# FM33A0XXER register map
File version: 1.0
CPU: SC000, little endian, no MPU, no FPU, 3 interrupt priority bits
Registers are 32-bit, read-write, reset 0x0 unless marked. A register's access mark holds for its fields unless they carry their own. Offsets are from the block's base; [hi:lo] are bit positions.

## UART — UART module information
Base 0x40017C00
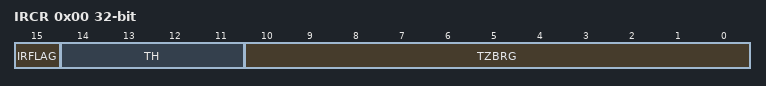
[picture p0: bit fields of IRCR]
0x00 IRCR — Infrared modulation Control Register
  [15] IRFLAG — IRFLAG field description
  [14:11] TH — TH field description
  [10:0] TZBRG — TZBRG field description

## UART0 — UART0 module information
Base 0x40012000
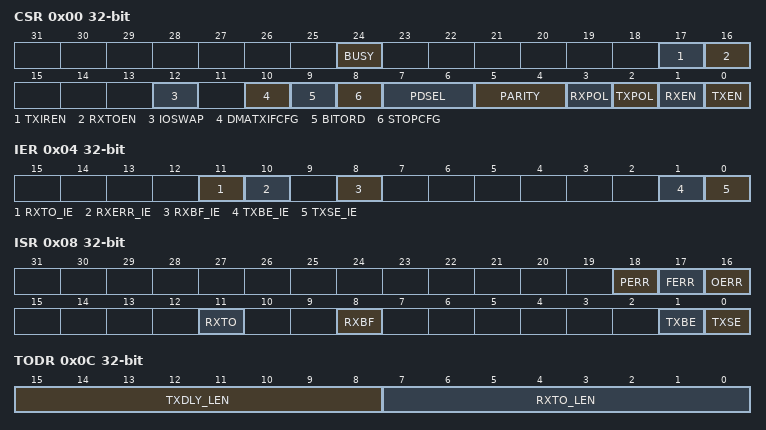
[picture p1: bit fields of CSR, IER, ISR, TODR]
0x00 CSR — UART0 Control Status Register
  [24] BUSY ro — BUSY field description
  [17] TXIREN — TXIREN field description
  [16] RXTOEN — RXTOEN field description
  [12] IOSWAP — IOSWAP field description
  [10] DMATXIFCFG — DMATXIFCFG field description
  [9] BITORD — BITORD field description
  [8] STOPCFG — STOPCFG field description
  [7:6] PDSEL — PDSEL field description
  [5:4] PARITY — PARITY field description
  [3] RXPOL — RXPOL field description
  [2] TXPOL — TXPOL field description
  [1] RXEN — RXEN field description
  [0] TXEN — TXEN field description
0x04 IER — UART0 Interrupt Enable Register
  [11] RXTO_IE — RXTO_IE field description
  [10] RXERR_IE — RXERR_IE field description
  [8] RXBF_IE — RXBF_IE field description
  [1] TXBE_IE — TXBE_IE field description
  [0] TXSE_IE — TXSE_IE field description
0x08 ISR — UART0 Interrupt Status Register
  [18] PERR — PERR field description
  [17] FERR — FERR field description
  [16] OERR — OERR field description
  [11] RXTO — RXTO field description
  [8] RXBF — RXBF field description
  [1] TXBE — TXBE field description
  [0] TXSE — TXSE field description
0x0C TODR — UART0 Time-Out and Delay Register
  [15:8] TXDLY_LEN — TXDLY_LEN field description
  [7:0] RXTO_LEN — RXTO_LEN field description
0x10 RXBUF — UART0 Receive Buffer
  [8:0] RXBUF ro — RXBUF field description
0x14 TXBUF — UART0 Transmit Buffer
  [8:0] TXBUF — TXBUF field description
0x18 BGR reset 0x341 — UART0 Baud rate Generator Register
  [15:0] SPBRG — SPBRG field description

## UART1 — UART1 module information
Base 0x40016800
Registers as UART0 (with UART0 read as UART1).

## UART2 — UART2 module information
Base 0x40016C00
Registers as UART0 (with UART0 read as UART2), without TODR.

## UART3 — UART3 module information
Base 0x40017000
Registers as UART0 (with UART0 read as UART3), without TODR; these are added or differ:
0x14 TXBUF — UART3Transmit Buffer
  [8:0] TXBUF — TXBUF field description

## UART4 — UART4 module information
Base 0x40017400
Registers as UART0 (with UART0 read as UART4), without TODR.

## UART5 — UART5 module information
Base 0x40017800
Registers as UART0 (with UART0 read as UART5), without TODR.

## LPUART0 — LPUART0 module information
Base 0x40014000
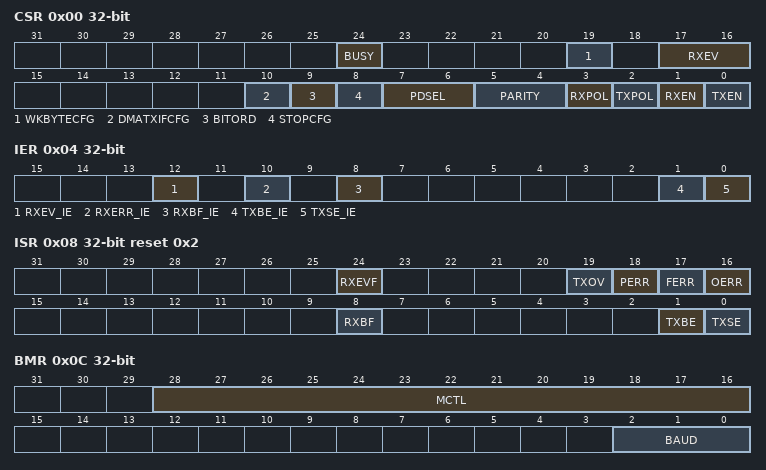
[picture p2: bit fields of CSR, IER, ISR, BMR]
0x00 CSR — LPUART0 Control Status Register
  [24] BUSY ro — BUSY field description
  [19] WKBYTECFG — WKBYTECFG field description
  [17:16] RXEV — RXEV field description
  [10] DMATXIFCFG — DMATXIFCFG field description
  [9] BITORD — BITORD field description
  [8] STOPCFG — STOPCFG field description
  [7:6] PDSEL — PDSEL field description
  [5:4] PARITY — PARITY field description
  [3] RXPOL — RXPOL field description
  [2] TXPOL — TXPOL field description
  [1] RXEN — RXEN field description
  [0] TXEN — TXEN field description
0x04 IER — LPUART0 Interrupt Enable Register
  [12] RXEV_IE — RXEV_IE field description
  [10] RXERR_IE — RXERR_IE field description
  [8] RXBF_IE — RXBF_IE field description
  [1] TXBE_IE — TXBE_IE field description
  [0] TXSE_IE — TXSE_IE field description
0x08 ISR reset 0x2 — LPUART0 Interrupt Status Register
  [24] RXEVF — RXEVF field description
  [19] TXOV — TXOV field description
  [18] PERR — PERR field description
  [17] FERR — FERR field description
  [16] OERR — OERR field description
  [8] RXBF — RXBF field description
  [1] TXBE ro — TXBE field description
  [0] TXSE — TXSE field description
0x0C BMR — LPUART0 Baud rate Modulation Register
  [28:16] MCTL — MCTL field description
  [2:0] BAUD — BAUD field description
0x10 RXBUF — LPUART0 Receive Buffer Register
  [8:0] RXBUF ro — RXBUF field description
0x14 TXBUF — LPUART0 Transmit Buffer Register
  [8:0] TXBUF — TXBUF field description
0x18 DMR — LPUART0 data Matching Register
  [8:0] MATD — MATD field description

## LPUART1 — LPUART1 module information
Base 0x40014400
Registers as LPUART0 (with LPUART0 read as LPUART1); these are added or differ:
0x10 RXBUF — LPUART1 Receive Data Register
  [8:0] RXBUF ro — RXBUF field description
0x14 TXBUF — LPUART1 Transmit Data Register
  [8:0] TXBUF — TXBUF field description
